AUTOSAR XML (schema 4-2-2)
package /COMPOSITION_PACKAGE
  sender receiver interface SR_LIGHT_CONTROL
    data LIGHT_CONTROL: type=uint16
  sender receiver interface SR_LIGHT_ACTUATE
    data LIGHT_ACTUATE: type=uint16
  sensor actuator sw component type SW_LIGHT_CONTROL
    provide port PROVIDER_LIGHT_CONTROL: provided-interface=SR_LIGHT_CONTROL
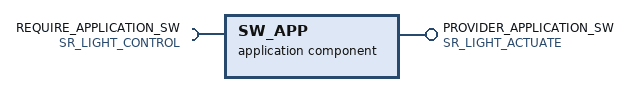
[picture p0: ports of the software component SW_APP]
  application sw component type SW_APP
    require port REQUIRE_APPLICATION_SW: required-interface=SR_LIGHT_CONTROL
    provide port PROVIDER_APPLICATION_SW: provided-interface=SR_LIGHT_ACTUATE
  sensor actuator sw component type SW_LIGHT_ACTUATE
    require port REQUESTER_LIGHT_ACTUATE: required-interface=SR_LIGHT_ACTUATE
  composition sw component type COMPOSITE1_SW1_SW2
    provide port PROVIDER_APPLICATION_SW: provided-interface=SR_LIGHT_ACTUATE
    component PROTO_LIGHT_CONTROL: type=SW_LIGHT_CONTROL
    component PROTO_APPLICATION_SW: type=SW_APP
    connect PROTO_LIGHT_CONTROL.PROVIDER_LIGHT_CONTROL -> PROTO_APPLICATION_SW.REQUIRE_APPLICATION_SW
    delegate PROTO_APPLICATION_SW.PROVIDER_APPLICATION_SW <-> outer port PROVIDER_APPLICATION_SW
  composition sw component type TOP_LEVEL_COMPOSITION
    component PROTO_COMPOSITE1: type=COMPOSITE1_SW1_SW2
    component PROTO_LIGHT_ACTUATOR: type=SW_LIGHT_ACTUATE
    connect PROTO_COMPOSITE1.PROTO_APPLICATION_SW -> PROTO_LIGHT_ACTUATOR.REQUESTER_LIGHT_ACTUATE
